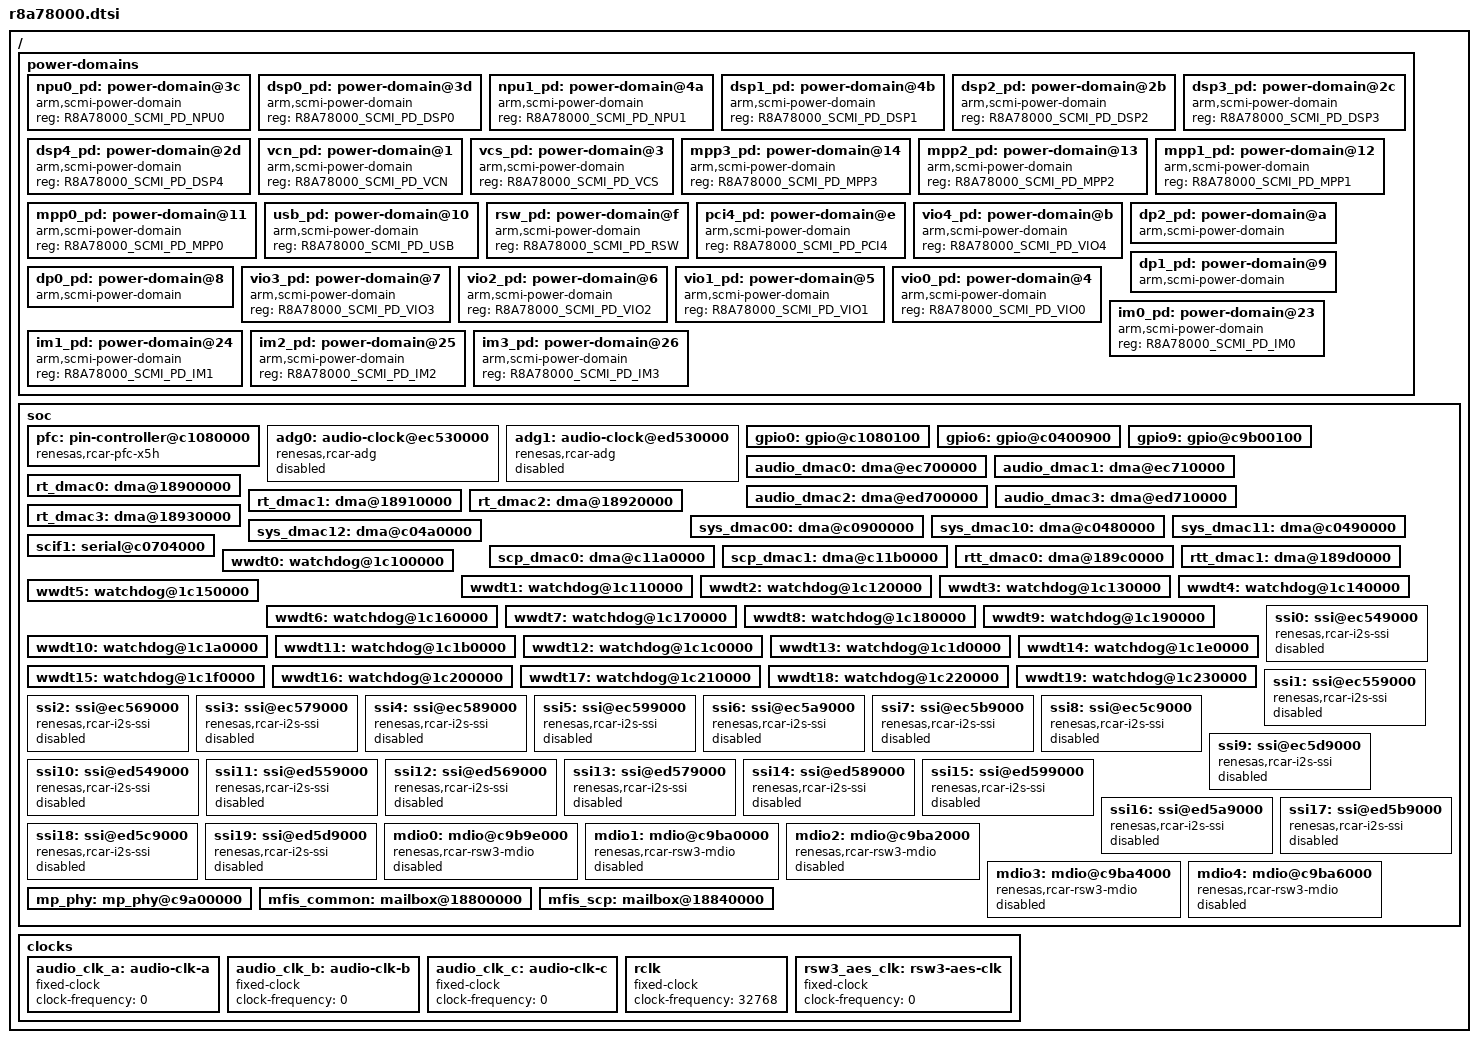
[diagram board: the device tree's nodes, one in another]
/*
 * Copyright (c) 2026 Renesas Electronics Corporation
 *
 * SPDX-License-Identifier: Apache-2.0
 */

#include <renesas/rcar/gen5/rcar_gen5_cr52.dtsi>
#include <zephyr/dt-bindings/clock/r8a78000_scmi_clock.h>
#include <zephyr/dt-bindings/clock/renesas_rcar_adg.h>
#include <zephyr/dt-bindings/power/r8a78000_scmi_power_domain.h>
#include <zephyr/dt-bindings/reset/r8a78000_scmi_reset_domain.h>

/ {
	power-domains {
		#address-cells = <1>;
		#size-cells = <0>;

		/*
		 * SCMI power domain IDs exported by the R-Car X5H V1 SCP firmware.
		 * These IDs index g_scmi_pd_config_table[] and are unrelated to the
		 * MDLC-local PDID values described by the hardware manual.
		 */
		npu0_pd: power-domain@3c {
			compatible = "arm,scmi-power-domain";
			reg = <R8A78000_SCMI_PD_NPU0>;
			#power-domain-cells = <0>;
		};

		dsp0_pd: power-domain@3d {
			compatible = "arm,scmi-power-domain";
			reg = <R8A78000_SCMI_PD_DSP0>;
			#power-domain-cells = <0>;
		};

		npu1_pd: power-domain@4a {
			compatible = "arm,scmi-power-domain";
			reg = <R8A78000_SCMI_PD_NPU1>;
			#power-domain-cells = <0>;
		};

		dsp1_pd: power-domain@4b {
			compatible = "arm,scmi-power-domain";
			reg = <R8A78000_SCMI_PD_DSP1>;
			#power-domain-cells = <0>;
		};

		dsp2_pd: power-domain@2b {
			compatible = "arm,scmi-power-domain";
			reg = <R8A78000_SCMI_PD_DSP2>;
			#power-domain-cells = <0>;
		};

		dsp3_pd: power-domain@2c {
			compatible = "arm,scmi-power-domain";
			reg = <R8A78000_SCMI_PD_DSP3>;
			#power-domain-cells = <0>;
		};

		dsp4_pd: power-domain@2d {
			compatible = "arm,scmi-power-domain";
			reg = <R8A78000_SCMI_PD_DSP4>;
			#power-domain-cells = <0>;
		};

		vcn_pd: power-domain@1 {
			compatible = "arm,scmi-power-domain";
			reg = <R8A78000_SCMI_PD_VCN>;
			#power-domain-cells = <0>;
		};

		vcs_pd: power-domain@3 {
			compatible = "arm,scmi-power-domain";
			reg = <R8A78000_SCMI_PD_VCS>;
			#power-domain-cells = <0>;
		};

		mpp3_pd: power-domain@14 {
			compatible = "arm,scmi-power-domain";
			reg = <R8A78000_SCMI_PD_MPP3>;
			#power-domain-cells = <0>;
		};

		mpp2_pd: power-domain@13 {
			compatible = "arm,scmi-power-domain";
			reg = <R8A78000_SCMI_PD_MPP2>;
			#power-domain-cells = <0>;
		};

		mpp1_pd: power-domain@12 {
			compatible = "arm,scmi-power-domain";
			reg = <R8A78000_SCMI_PD_MPP1>;
			#power-domain-cells = <0>;
		};

		mpp0_pd: power-domain@11 {
			compatible = "arm,scmi-power-domain";
			reg = <R8A78000_SCMI_PD_MPP0>;
			#power-domain-cells = <0>;
		};

		usb_pd: power-domain@10 {
			compatible = "arm,scmi-power-domain";
			reg = <R8A78000_SCMI_PD_USB>;
			#power-domain-cells = <0>;
		};

		rsw_pd: power-domain@f {
			compatible = "arm,scmi-power-domain";
			reg = <R8A78000_SCMI_PD_RSW>;
			#power-domain-cells = <0>;
		};

		pci4_pd: power-domain@e {
			compatible = "arm,scmi-power-domain";
			reg = <R8A78000_SCMI_PD_PCI4>;
			#power-domain-cells = <0>;
		};

		vio4_pd: power-domain@b {
			compatible = "arm,scmi-power-domain";
			reg = <R8A78000_SCMI_PD_VIO4>;
			#power-domain-cells = <0>;
		};

		dp2_pd: power-domain@a {
			compatible = "arm,scmi-power-domain";
			reg = <R8A78000_SCMI_PD_DP2>;
			#power-domain-cells = <0>;
			power-domains = <&vio4_pd>;
		};

		dp1_pd: power-domain@9 {
			compatible = "arm,scmi-power-domain";
			reg = <R8A78000_SCMI_PD_DP1>;
			#power-domain-cells = <0>;
			power-domains = <&vio4_pd>;
		};

		dp0_pd: power-domain@8 {
			compatible = "arm,scmi-power-domain";
			reg = <R8A78000_SCMI_PD_DP0>;
			#power-domain-cells = <0>;
			power-domains = <&vio4_pd>;
		};

		vio3_pd: power-domain@7 {
			compatible = "arm,scmi-power-domain";
			reg = <R8A78000_SCMI_PD_VIO3>;
			#power-domain-cells = <0>;
		};

		vio2_pd: power-domain@6 {
			compatible = "arm,scmi-power-domain";
			reg = <R8A78000_SCMI_PD_VIO2>;
			#power-domain-cells = <0>;
		};

		vio1_pd: power-domain@5 {
			compatible = "arm,scmi-power-domain";
			reg = <R8A78000_SCMI_PD_VIO1>;
			#power-domain-cells = <0>;
		};

		vio0_pd: power-domain@4 {
			compatible = "arm,scmi-power-domain";
			reg = <R8A78000_SCMI_PD_VIO0>;
			#power-domain-cells = <0>;
		};

		im0_pd: power-domain@23 {
			compatible = "arm,scmi-power-domain";
			reg = <R8A78000_SCMI_PD_IM0>;
			#power-domain-cells = <0>;
		};

		im1_pd: power-domain@24 {
			compatible = "arm,scmi-power-domain";
			reg = <R8A78000_SCMI_PD_IM1>;
			#power-domain-cells = <0>;
		};

		im2_pd: power-domain@25 {
			compatible = "arm,scmi-power-domain";
			reg = <R8A78000_SCMI_PD_IM2>;
			#power-domain-cells = <0>;
		};

		im3_pd: power-domain@26 {
			compatible = "arm,scmi-power-domain";
			reg = <R8A78000_SCMI_PD_IM3>;
			#power-domain-cells = <0>;
		};
	};

	soc {
		pfc: pin-controller@c1080000 {
			compatible = "renesas,rcar-pfc-x5h";
			reg = <0xc1080000 0x16c>, <0xc1080800 0x16c>,
			      <0xc1081000 0x16c>, <0xc0800000 0x16c>,
			      <0xc0800800 0x16c>, <0xc0400000 0x16c>,
			      <0xc0400800 0x16c>, <0xc0401000 0x16c>,
			      <0xc0401800 0x16c>, <0xc9b00000 0x16c>,
			      <0xc9b00800 0x16c>;
		};

		adg0: audio-clock@ec530000 {
			compatible = "renesas,rcar-adg";
			reg = <0xec530000 0x140>;
			clocks = <&scmi_clk R8A78000_SCMI_CLK_ADG0>,
				 <&scmi_clk R8A78000_SCMI_CLK_ADGHD1CK_MP_BUS>,
				 <&scmi_clk R8A78000_SCMI_CLK_ADGHD4CK_MP_BUS>,
				 <&audio_clk_a>, <&audio_clk_b>, <&audio_clk_c>;
			clock-names = "pclk", "s0d1", "s0d4",
				      "clk_a", "clk_b", "clk_c";
			#clock-cells = <1>;
			audio-clkout-sel = <ADG_CLKSRC(NONE) ADG_CLKSRC(NONE)
					    ADG_CLKSRC(NONE) ADG_CLKSRC(NONE)>;
			brga-clk-sel = <ADG_BRGSRC(S0D4)>;
			brgb-clk-sel = <ADG_BRGSRC(S0D4)>;
			status = "disabled";
		};

		adg1: audio-clock@ed530000 {
			compatible = "renesas,rcar-adg";
			reg = <0xed530000 0x140>;
			clocks = <&scmi_clk R8A78000_SCMI_CLK_ADG1>,
				 <&scmi_clk R8A78000_SCMI_CLK_ADGHD1CK_MP_BUS>,
				 <&scmi_clk R8A78000_SCMI_CLK_ADGHD4CK_MP_BUS>,
				 <&audio_clk_a>, <&audio_clk_b>, <&audio_clk_c>;
			clock-names = "pclk", "s0d1", "s0d4",
				      "clk_a", "clk_b", "clk_c";
			#clock-cells = <1>;
			audio-clkout-sel = <ADG_CLKSRC(NONE) ADG_CLKSRC(NONE)
					    ADG_CLKSRC(NONE) ADG_CLKSRC(NONE)>;
			brga-clk-sel = <ADG_BRGSRC(S0D4)>;
			brgb-clk-sel = <ADG_BRGSRC(S0D4)>;
			status = "disabled";
		};

		gpio0: gpio@c1080100 {
			interrupts = <GIC_SPI 0 IRQ_TYPE_LEVEL IRQ_DEFAULT_PRIORITY>;
			clocks = <&scmi_clk R8A78000_SCMI_CLK_PERE_GPIODM0>;
		};

		gpio6: gpio@c0400900 {
			interrupts = <GIC_SPI 24 IRQ_TYPE_LEVEL IRQ_DEFAULT_PRIORITY>;
			clocks = <&scmi_clk R8A78000_SCMI_CLK_PERE_GPIODM0>;
		};

		gpio9: gpio@c9b00100 {
			interrupts = <GIC_SPI 36 IRQ_TYPE_LEVEL IRQ_DEFAULT_PRIORITY>;
			clocks = <&scmi_clk R8A78000_SCMI_CLK_PERE_GPIODM0>;
		};

		audio_dmac0: dma@ec700000 {
			interrupts = <GIC_SPI 202 IRQ_TYPE_LEVEL IRQ_DEFAULT_PRIORITY>,
				     <GIC_SPI 203 IRQ_TYPE_LEVEL IRQ_DEFAULT_PRIORITY>,
				     <GIC_SPI 204 IRQ_TYPE_LEVEL IRQ_DEFAULT_PRIORITY>,
				     <GIC_SPI 205 IRQ_TYPE_LEVEL IRQ_DEFAULT_PRIORITY>,
				     <GIC_SPI 206 IRQ_TYPE_LEVEL IRQ_DEFAULT_PRIORITY>,
				     <GIC_SPI 207 IRQ_TYPE_LEVEL IRQ_DEFAULT_PRIORITY>,
				     <GIC_SPI 208 IRQ_TYPE_LEVEL IRQ_DEFAULT_PRIORITY>,
				     <GIC_SPI 209 IRQ_TYPE_LEVEL IRQ_DEFAULT_PRIORITY>;
			interrupt-names = "ch0", "ch2", "ch4", "ch6",
					  "ch8", "ch10", "ch12", "ch14";
		};

		audio_dmac1: dma@ec710000 {
			interrupts = <GIC_SPI 210 IRQ_TYPE_LEVEL IRQ_DEFAULT_PRIORITY>,
				     <GIC_SPI 211 IRQ_TYPE_LEVEL IRQ_DEFAULT_PRIORITY>,
				     <GIC_SPI 212 IRQ_TYPE_LEVEL IRQ_DEFAULT_PRIORITY>,
				     <GIC_SPI 213 IRQ_TYPE_LEVEL IRQ_DEFAULT_PRIORITY>,
				     <GIC_SPI 214 IRQ_TYPE_LEVEL IRQ_DEFAULT_PRIORITY>,
				     <GIC_SPI 215 IRQ_TYPE_LEVEL IRQ_DEFAULT_PRIORITY>,
				     <GIC_SPI 216 IRQ_TYPE_LEVEL IRQ_DEFAULT_PRIORITY>,
				     <GIC_SPI 217 IRQ_TYPE_LEVEL IRQ_DEFAULT_PRIORITY>;
			interrupt-names = "ch0", "ch2", "ch4", "ch6",
					  "ch8", "ch10", "ch12", "ch14";
		};

		audio_dmac2: dma@ed700000 {
			interrupts = <GIC_SPI 218 IRQ_TYPE_LEVEL IRQ_DEFAULT_PRIORITY>,
				     <GIC_SPI 219 IRQ_TYPE_LEVEL IRQ_DEFAULT_PRIORITY>,
				     <GIC_SPI 220 IRQ_TYPE_LEVEL IRQ_DEFAULT_PRIORITY>,
				     <GIC_SPI 221 IRQ_TYPE_LEVEL IRQ_DEFAULT_PRIORITY>,
				     <GIC_SPI 222 IRQ_TYPE_LEVEL IRQ_DEFAULT_PRIORITY>,
				     <GIC_SPI 223 IRQ_TYPE_LEVEL IRQ_DEFAULT_PRIORITY>,
				     <GIC_SPI 224 IRQ_TYPE_LEVEL IRQ_DEFAULT_PRIORITY>,
				     <GIC_SPI 225 IRQ_TYPE_LEVEL IRQ_DEFAULT_PRIORITY>;
			interrupt-names = "ch0", "ch2", "ch4", "ch6",
					  "ch8", "ch10", "ch12", "ch14";
		};

		audio_dmac3: dma@ed710000 {
			interrupts = <GIC_SPI 226 IRQ_TYPE_LEVEL IRQ_DEFAULT_PRIORITY>,
				     <GIC_SPI 227 IRQ_TYPE_LEVEL IRQ_DEFAULT_PRIORITY>,
				     <GIC_SPI 228 IRQ_TYPE_LEVEL IRQ_DEFAULT_PRIORITY>,
				     <GIC_SPI 229 IRQ_TYPE_LEVEL IRQ_DEFAULT_PRIORITY>,
				     <GIC_SPI 230 IRQ_TYPE_LEVEL IRQ_DEFAULT_PRIORITY>,
				     <GIC_SPI 231 IRQ_TYPE_LEVEL IRQ_DEFAULT_PRIORITY>,
				     <GIC_SPI 232 IRQ_TYPE_LEVEL IRQ_DEFAULT_PRIORITY>,
				     <GIC_SPI 233 IRQ_TYPE_LEVEL IRQ_DEFAULT_PRIORITY>;
			interrupt-names = "ch0", "ch2", "ch4", "ch6",
					  "ch8", "ch10", "ch12", "ch14";
		};

		rt_dmac0: dma@18900000 {
			interrupts = <GIC_SPI 242 IRQ_TYPE_LEVEL IRQ_DEFAULT_PRIORITY>,
				     <GIC_SPI 243 IRQ_TYPE_LEVEL IRQ_DEFAULT_PRIORITY>,
				     <GIC_SPI 244 IRQ_TYPE_LEVEL IRQ_DEFAULT_PRIORITY>,
				     <GIC_SPI 245 IRQ_TYPE_LEVEL IRQ_DEFAULT_PRIORITY>,
				     <GIC_SPI 246 IRQ_TYPE_LEVEL IRQ_DEFAULT_PRIORITY>,
				     <GIC_SPI 247 IRQ_TYPE_LEVEL IRQ_DEFAULT_PRIORITY>,
				     <GIC_SPI 248 IRQ_TYPE_LEVEL IRQ_DEFAULT_PRIORITY>,
				     <GIC_SPI 249 IRQ_TYPE_LEVEL IRQ_DEFAULT_PRIORITY>;
			interrupt-names = "ch0", "ch2", "ch4", "ch6",
					  "ch8", "ch10", "ch12", "ch14";
		};

		rt_dmac1: dma@18910000 {
			interrupts = <GIC_SPI 250 IRQ_TYPE_LEVEL IRQ_DEFAULT_PRIORITY>,
				     <GIC_SPI 251 IRQ_TYPE_LEVEL IRQ_DEFAULT_PRIORITY>,
				     <GIC_SPI 252 IRQ_TYPE_LEVEL IRQ_DEFAULT_PRIORITY>,
				     <GIC_SPI 253 IRQ_TYPE_LEVEL IRQ_DEFAULT_PRIORITY>,
				     <GIC_SPI 254 IRQ_TYPE_LEVEL IRQ_DEFAULT_PRIORITY>,
				     <GIC_SPI 255 IRQ_TYPE_LEVEL IRQ_DEFAULT_PRIORITY>,
				     <GIC_SPI 256 IRQ_TYPE_LEVEL IRQ_DEFAULT_PRIORITY>,
				     <GIC_SPI 257 IRQ_TYPE_LEVEL IRQ_DEFAULT_PRIORITY>;
			interrupt-names = "ch0", "ch2", "ch4", "ch6",
					  "ch8", "ch10", "ch12", "ch14";
		};

		rt_dmac2: dma@18920000 {
			interrupts = <GIC_SPI 258 IRQ_TYPE_LEVEL IRQ_DEFAULT_PRIORITY>,
				     <GIC_SPI 259 IRQ_TYPE_LEVEL IRQ_DEFAULT_PRIORITY>,
				     <GIC_SPI 260 IRQ_TYPE_LEVEL IRQ_DEFAULT_PRIORITY>,
				     <GIC_SPI 261 IRQ_TYPE_LEVEL IRQ_DEFAULT_PRIORITY>,
				     <GIC_SPI 262 IRQ_TYPE_LEVEL IRQ_DEFAULT_PRIORITY>,
				     <GIC_SPI 263 IRQ_TYPE_LEVEL IRQ_DEFAULT_PRIORITY>,
				     <GIC_SPI 264 IRQ_TYPE_LEVEL IRQ_DEFAULT_PRIORITY>,
				     <GIC_SPI 265 IRQ_TYPE_LEVEL IRQ_DEFAULT_PRIORITY>;
			interrupt-names = "ch0", "ch2", "ch4", "ch6",
					  "ch8", "ch10", "ch12", "ch14";
		};

		rt_dmac3: dma@18930000 {
			interrupts = <GIC_SPI 266 IRQ_TYPE_LEVEL IRQ_DEFAULT_PRIORITY>,
				     <GIC_SPI 267 IRQ_TYPE_LEVEL IRQ_DEFAULT_PRIORITY>,
				     <GIC_SPI 268 IRQ_TYPE_LEVEL IRQ_DEFAULT_PRIORITY>,
				     <GIC_SPI 269 IRQ_TYPE_LEVEL IRQ_DEFAULT_PRIORITY>,
				     <GIC_SPI 270 IRQ_TYPE_LEVEL IRQ_DEFAULT_PRIORITY>,
				     <GIC_SPI 271 IRQ_TYPE_LEVEL IRQ_DEFAULT_PRIORITY>,
				     <GIC_SPI 272 IRQ_TYPE_LEVEL IRQ_DEFAULT_PRIORITY>,
				     <GIC_SPI 273 IRQ_TYPE_LEVEL IRQ_DEFAULT_PRIORITY>;
			interrupt-names = "ch0", "ch2", "ch4", "ch6",
					  "ch8", "ch10", "ch12", "ch14";
		};

		sys_dmac00: dma@c0900000 {
			interrupts = <GIC_SPI 282 IRQ_TYPE_LEVEL IRQ_DEFAULT_PRIORITY>,
				     <GIC_SPI 283 IRQ_TYPE_LEVEL IRQ_DEFAULT_PRIORITY>,
				     <GIC_SPI 284 IRQ_TYPE_LEVEL IRQ_DEFAULT_PRIORITY>,
				     <GIC_SPI 285 IRQ_TYPE_LEVEL IRQ_DEFAULT_PRIORITY>,
				     <GIC_SPI 286 IRQ_TYPE_LEVEL IRQ_DEFAULT_PRIORITY>,
				     <GIC_SPI 287 IRQ_TYPE_LEVEL IRQ_DEFAULT_PRIORITY>,
				     <GIC_SPI 288 IRQ_TYPE_LEVEL IRQ_DEFAULT_PRIORITY>,
				     <GIC_SPI 289 IRQ_TYPE_LEVEL IRQ_DEFAULT_PRIORITY>;
			interrupt-names = "ch0", "ch2", "ch4", "ch6",
					  "ch8", "ch10", "ch12", "ch14";
		};

		sys_dmac10: dma@c0480000 {
			interrupts = <GIC_SPI 290 IRQ_TYPE_LEVEL IRQ_DEFAULT_PRIORITY>,
				     <GIC_SPI 291 IRQ_TYPE_LEVEL IRQ_DEFAULT_PRIORITY>,
				     <GIC_SPI 292 IRQ_TYPE_LEVEL IRQ_DEFAULT_PRIORITY>,
				     <GIC_SPI 293 IRQ_TYPE_LEVEL IRQ_DEFAULT_PRIORITY>,
				     <GIC_SPI 294 IRQ_TYPE_LEVEL IRQ_DEFAULT_PRIORITY>,
				     <GIC_SPI 295 IRQ_TYPE_LEVEL IRQ_DEFAULT_PRIORITY>,
				     <GIC_SPI 296 IRQ_TYPE_LEVEL IRQ_DEFAULT_PRIORITY>,
				     <GIC_SPI 297 IRQ_TYPE_LEVEL IRQ_DEFAULT_PRIORITY>;
			interrupt-names = "ch0", "ch2", "ch4", "ch6",
					  "ch8", "ch10", "ch12", "ch14";
		};

		sys_dmac11: dma@c0490000 {
			interrupts = <GIC_SPI 298 IRQ_TYPE_LEVEL IRQ_DEFAULT_PRIORITY>,
				     <GIC_SPI 299 IRQ_TYPE_LEVEL IRQ_DEFAULT_PRIORITY>,
				     <GIC_SPI 300 IRQ_TYPE_LEVEL IRQ_DEFAULT_PRIORITY>,
				     <GIC_SPI 301 IRQ_TYPE_LEVEL IRQ_DEFAULT_PRIORITY>,
				     <GIC_SPI 302 IRQ_TYPE_LEVEL IRQ_DEFAULT_PRIORITY>,
				     <GIC_SPI 303 IRQ_TYPE_LEVEL IRQ_DEFAULT_PRIORITY>,
				     <GIC_SPI 304 IRQ_TYPE_LEVEL IRQ_DEFAULT_PRIORITY>,
				     <GIC_SPI 305 IRQ_TYPE_LEVEL IRQ_DEFAULT_PRIORITY>;
			interrupt-names = "ch0", "ch2", "ch4", "ch6",
					  "ch8", "ch10", "ch12", "ch14";
		};

		sys_dmac12: dma@c04a0000 {
			interrupts = <GIC_SPI 306 IRQ_TYPE_LEVEL IRQ_DEFAULT_PRIORITY>,
				     <GIC_SPI 307 IRQ_TYPE_LEVEL IRQ_DEFAULT_PRIORITY>,
				     <GIC_SPI 308 IRQ_TYPE_LEVEL IRQ_DEFAULT_PRIORITY>,
				     <GIC_SPI 309 IRQ_TYPE_LEVEL IRQ_DEFAULT_PRIORITY>,
				     <GIC_SPI 310 IRQ_TYPE_LEVEL IRQ_DEFAULT_PRIORITY>,
				     <GIC_SPI 311 IRQ_TYPE_LEVEL IRQ_DEFAULT_PRIORITY>,
				     <GIC_SPI 312 IRQ_TYPE_LEVEL IRQ_DEFAULT_PRIORITY>,
				     <GIC_SPI 313 IRQ_TYPE_LEVEL IRQ_DEFAULT_PRIORITY>;
			interrupt-names = "ch0", "ch2", "ch4", "ch6",
					  "ch8", "ch10", "ch12", "ch14";
		};

		scp_dmac0: dma@c11a0000 {
			interrupts = <GIC_SPI 793 IRQ_TYPE_LEVEL IRQ_DEFAULT_PRIORITY>,
				     <GIC_SPI 794 IRQ_TYPE_LEVEL IRQ_DEFAULT_PRIORITY>,
				     <GIC_SPI 795 IRQ_TYPE_LEVEL IRQ_DEFAULT_PRIORITY>,
				     <GIC_SPI 796 IRQ_TYPE_LEVEL IRQ_DEFAULT_PRIORITY>,
				     <GIC_SPI 797 IRQ_TYPE_LEVEL IRQ_DEFAULT_PRIORITY>,
				     <GIC_SPI 798 IRQ_TYPE_LEVEL IRQ_DEFAULT_PRIORITY>,
				     <GIC_SPI 799 IRQ_TYPE_LEVEL IRQ_DEFAULT_PRIORITY>,
				     <GIC_SPI 800 IRQ_TYPE_LEVEL IRQ_DEFAULT_PRIORITY>;
			interrupt-names = "ch0", "ch2", "ch4", "ch6",
					  "ch8", "ch10", "ch12", "ch14";
		};

		scp_dmac1: dma@c11b0000 {
			interrupts = <GIC_SPI 803 IRQ_TYPE_LEVEL IRQ_DEFAULT_PRIORITY>,
				     <GIC_SPI 804 IRQ_TYPE_LEVEL IRQ_DEFAULT_PRIORITY>,
				     <GIC_SPI 805 IRQ_TYPE_LEVEL IRQ_DEFAULT_PRIORITY>,
				     <GIC_SPI 806 IRQ_TYPE_LEVEL IRQ_DEFAULT_PRIORITY>,
				     <GIC_SPI 807 IRQ_TYPE_LEVEL IRQ_DEFAULT_PRIORITY>,
				     <GIC_SPI 808 IRQ_TYPE_LEVEL IRQ_DEFAULT_PRIORITY>,
				     <GIC_SPI 809 IRQ_TYPE_LEVEL IRQ_DEFAULT_PRIORITY>,
				     <GIC_SPI 810 IRQ_TYPE_LEVEL IRQ_DEFAULT_PRIORITY>;
			interrupt-names = "ch0", "ch2", "ch4", "ch6",
					  "ch8", "ch10", "ch12", "ch14";
		};

		rtt_dmac0: dma@189c0000 {
			interrupts = <GIC_SPI 732 IRQ_TYPE_LEVEL IRQ_DEFAULT_PRIORITY>,
				     <GIC_SPI 733 IRQ_TYPE_LEVEL IRQ_DEFAULT_PRIORITY>,
				     <GIC_SPI 734 IRQ_TYPE_LEVEL IRQ_DEFAULT_PRIORITY>,
				     <GIC_SPI 735 IRQ_TYPE_LEVEL IRQ_DEFAULT_PRIORITY>,
				     <GIC_SPI 736 IRQ_TYPE_LEVEL IRQ_DEFAULT_PRIORITY>,
				     <GIC_SPI 737 IRQ_TYPE_LEVEL IRQ_DEFAULT_PRIORITY>,
				     <GIC_SPI 738 IRQ_TYPE_LEVEL IRQ_DEFAULT_PRIORITY>,
				     <GIC_SPI 739 IRQ_TYPE_LEVEL IRQ_DEFAULT_PRIORITY>,
				     <GIC_SPI 740 IRQ_TYPE_LEVEL IRQ_DEFAULT_PRIORITY>,
				     <GIC_SPI 741 IRQ_TYPE_LEVEL IRQ_DEFAULT_PRIORITY>,
				     <GIC_SPI 742 IRQ_TYPE_LEVEL IRQ_DEFAULT_PRIORITY>,
				     <GIC_SPI 743 IRQ_TYPE_LEVEL IRQ_DEFAULT_PRIORITY>,
				     <GIC_SPI 744 IRQ_TYPE_LEVEL IRQ_DEFAULT_PRIORITY>,
				     <GIC_SPI 745 IRQ_TYPE_LEVEL IRQ_DEFAULT_PRIORITY>,
				     <GIC_SPI 746 IRQ_TYPE_LEVEL IRQ_DEFAULT_PRIORITY>,
				     <GIC_SPI 747 IRQ_TYPE_LEVEL IRQ_DEFAULT_PRIORITY>;
			interrupt-names = "ch0", "ch1", "ch2", "ch3",
					  "ch4", "ch5", "ch6", "ch7",
					  "ch8", "ch9", "ch10", "ch11",
					  "ch12", "ch13", "ch14", "ch15";
		};

		rtt_dmac1: dma@189d0000 {
			interrupts = <GIC_SPI 748 IRQ_TYPE_LEVEL IRQ_DEFAULT_PRIORITY>,
				     <GIC_SPI 749 IRQ_TYPE_LEVEL IRQ_DEFAULT_PRIORITY>,
				     <GIC_SPI 750 IRQ_TYPE_LEVEL IRQ_DEFAULT_PRIORITY>,
				     <GIC_SPI 751 IRQ_TYPE_LEVEL IRQ_DEFAULT_PRIORITY>,
				     <GIC_SPI 752 IRQ_TYPE_LEVEL IRQ_DEFAULT_PRIORITY>,
				     <GIC_SPI 753 IRQ_TYPE_LEVEL IRQ_DEFAULT_PRIORITY>,
				     <GIC_SPI 754 IRQ_TYPE_LEVEL IRQ_DEFAULT_PRIORITY>,
				     <GIC_SPI 755 IRQ_TYPE_LEVEL IRQ_DEFAULT_PRIORITY>,
				     <GIC_SPI 756 IRQ_TYPE_LEVEL IRQ_DEFAULT_PRIORITY>,
				     <GIC_SPI 757 IRQ_TYPE_LEVEL IRQ_DEFAULT_PRIORITY>,
				     <GIC_SPI 758 IRQ_TYPE_LEVEL IRQ_DEFAULT_PRIORITY>,
				     <GIC_SPI 759 IRQ_TYPE_LEVEL IRQ_DEFAULT_PRIORITY>,
				     <GIC_SPI 760 IRQ_TYPE_LEVEL IRQ_DEFAULT_PRIORITY>,
				     <GIC_SPI 761 IRQ_TYPE_LEVEL IRQ_DEFAULT_PRIORITY>,
				     <GIC_SPI 762 IRQ_TYPE_LEVEL IRQ_DEFAULT_PRIORITY>,
				     <GIC_SPI 763 IRQ_TYPE_LEVEL IRQ_DEFAULT_PRIORITY>;
			interrupt-names = "ch0", "ch1", "ch2", "ch3",
					  "ch4", "ch5", "ch6", "ch7",
					  "ch8", "ch9", "ch10", "ch11",
					  "ch12", "ch13", "ch14", "ch15";
		};

		scif1: serial@c0704000 {
			interrupts = <GIC_SPI 588 IRQ_TYPE_LEVEL IRQ_DEFAULT_PRIORITY>;
			clocks = <&scmi_clk R8A78000_SCMI_CLK_SCIF1>, /* Mod clk */
				 <&scmi_clk R8A78000_SCMI_CLK_SGAD16_PERW_BUS>; /* Bus clk */
		};

		wwdt0: watchdog@1c100000 {
			interrupts = <GIC_SPI 655 IRQ_TYPE_LEVEL IRQ_DEFAULT_PRIORITY>;
			clocks = <&rclk>;
			resets = <&scmi_reset R8A78000_SCMI_RESET_WWDT00>,
				 <&scmi_reset R8A78000_SCMI_RESET_WWDT01>;
			warning-irq-enabled;
		};

		wwdt1: watchdog@1c110000 {
			interrupts = <GIC_SPI 656 IRQ_TYPE_LEVEL IRQ_DEFAULT_PRIORITY>;
			clocks = <&rclk>;
			resets = <&scmi_reset R8A78000_SCMI_RESET_WWDT10>,
				 <&scmi_reset R8A78000_SCMI_RESET_WWDT11>;
			warning-irq-enabled;
		};

		wwdt2: watchdog@1c120000 {
			interrupts = <GIC_SPI 657 IRQ_TYPE_LEVEL IRQ_DEFAULT_PRIORITY>;
			clocks = <&rclk>;
			resets = <&scmi_reset R8A78000_SCMI_RESET_WWDT20>,
				 <&scmi_reset R8A78000_SCMI_RESET_WWDT21>;
			warning-irq-enabled;
		};

		wwdt3: watchdog@1c130000 {
			interrupts = <GIC_SPI 658 IRQ_TYPE_LEVEL IRQ_DEFAULT_PRIORITY>;
			clocks = <&rclk>;
			resets = <&scmi_reset R8A78000_SCMI_RESET_WWDT30>,
				 <&scmi_reset R8A78000_SCMI_RESET_WWDT31>;
			warning-irq-enabled;
		};

		wwdt4: watchdog@1c140000 {
			interrupts = <GIC_SPI 659 IRQ_TYPE_LEVEL IRQ_DEFAULT_PRIORITY>;
			clocks = <&rclk>;
			resets = <&scmi_reset R8A78000_SCMI_RESET_WWDT40>,
				 <&scmi_reset R8A78000_SCMI_RESET_WWDT41>;
			warning-irq-enabled;
		};

		wwdt5: watchdog@1c150000 {
			interrupts = <GIC_SPI 660 IRQ_TYPE_LEVEL IRQ_DEFAULT_PRIORITY>;
			clocks = <&rclk>;
			resets = <&scmi_reset R8A78000_SCMI_RESET_WWDT50>,
				 <&scmi_reset R8A78000_SCMI_RESET_WWDT51>;
			warning-irq-enabled;
		};

		wwdt6: watchdog@1c160000 {
			interrupts = <GIC_SPI 661 IRQ_TYPE_LEVEL IRQ_DEFAULT_PRIORITY>;
			clocks = <&rclk>;
			resets = <&scmi_reset R8A78000_SCMI_RESET_WWDT60>,
				 <&scmi_reset R8A78000_SCMI_RESET_WWDT61>;
			warning-irq-enabled;
		};

		wwdt7: watchdog@1c170000 {
			interrupts = <GIC_SPI 662 IRQ_TYPE_LEVEL IRQ_DEFAULT_PRIORITY>;
			clocks = <&rclk>;
			resets = <&scmi_reset R8A78000_SCMI_RESET_WWDT70>,
				 <&scmi_reset R8A78000_SCMI_RESET_WWDT71>;
			warning-irq-enabled;
		};

		wwdt8: watchdog@1c180000 {
			interrupts = <GIC_SPI 663 IRQ_TYPE_LEVEL IRQ_DEFAULT_PRIORITY>;
			clocks = <&rclk>;
			resets = <&scmi_reset R8A78000_SCMI_RESET_WWDT80>,
				 <&scmi_reset R8A78000_SCMI_RESET_WWDT81>;
			warning-irq-enabled;
		};

		wwdt9: watchdog@1c190000 {
			interrupts = <GIC_SPI 664 IRQ_TYPE_LEVEL IRQ_DEFAULT_PRIORITY>;
			clocks = <&rclk>;
			resets = <&scmi_reset R8A78000_SCMI_RESET_WWDT90>,
				 <&scmi_reset R8A78000_SCMI_RESET_WWDT91>;
			warning-irq-enabled;
		};

		wwdt10: watchdog@1c1a0000 {
			interrupts = <GIC_SPI 665 IRQ_TYPE_LEVEL IRQ_DEFAULT_PRIORITY>;
			clocks = <&rclk>;
			resets = <&scmi_reset R8A78000_SCMI_RESET_WWDT100>,
				 <&scmi_reset R8A78000_SCMI_RESET_WWDT101>;
			warning-irq-enabled;
		};

		wwdt11: watchdog@1c1b0000 {
			interrupts = <GIC_SPI 666 IRQ_TYPE_LEVEL IRQ_DEFAULT_PRIORITY>;
			clocks = <&rclk>;
			resets = <&scmi_reset R8A78000_SCMI_RESET_WWDT110>,
				 <&scmi_reset R8A78000_SCMI_RESET_WWDT111>;
			warning-irq-enabled;
		};

		wwdt12: watchdog@1c1c0000 {
			interrupts = <GIC_SPI 667 IRQ_TYPE_LEVEL IRQ_DEFAULT_PRIORITY>;
			clocks = <&rclk>;
			resets = <&scmi_reset R8A78000_SCMI_RESET_WWDT120>,
				 <&scmi_reset R8A78000_SCMI_RESET_WWDT121>;
			warning-irq-enabled;
		};

		wwdt13: watchdog@1c1d0000 {
			interrupts = <GIC_SPI 668 IRQ_TYPE_LEVEL IRQ_DEFAULT_PRIORITY>;
			clocks = <&rclk>;
			resets = <&scmi_reset R8A78000_SCMI_RESET_WWDT130>,
				 <&scmi_reset R8A78000_SCMI_RESET_WWDT131>;
			warning-irq-enabled;
		};

		wwdt14: watchdog@1c1e0000 {
			interrupts = <GIC_SPI 669 IRQ_TYPE_LEVEL IRQ_DEFAULT_PRIORITY>;
			clocks = <&rclk>;
			resets = <&scmi_reset R8A78000_SCMI_RESET_WWDT140>,
				 <&scmi_reset R8A78000_SCMI_RESET_WWDT141>;
			warning-irq-enabled;
		};

		wwdt15: watchdog@1c1f0000 {
			interrupts = <GIC_SPI 670 IRQ_TYPE_LEVEL IRQ_DEFAULT_PRIORITY>;
			clocks = <&rclk>;
			resets = <&scmi_reset R8A78000_SCMI_RESET_WWDT150>,
				 <&scmi_reset R8A78000_SCMI_RESET_WWDT151>;
			warning-irq-enabled;
		};

		wwdt16: watchdog@1c200000 {
			interrupts = <GIC_SPI 671 IRQ_TYPE_LEVEL IRQ_DEFAULT_PRIORITY>;
			clocks = <&rclk>;
			resets = <&scmi_reset R8A78000_SCMI_RESET_WWDT160>,
				 <&scmi_reset R8A78000_SCMI_RESET_WWDT161>;
			warning-irq-enabled;
		};

		wwdt17: watchdog@1c210000 {
			interrupts = <GIC_SPI 672 IRQ_TYPE_LEVEL IRQ_DEFAULT_PRIORITY>;
			clocks = <&rclk>;
			resets = <&scmi_reset R8A78000_SCMI_RESET_WWDT170>,
				 <&scmi_reset R8A78000_SCMI_RESET_WWDT171>;
			warning-irq-enabled;
		};

		wwdt18: watchdog@1c220000 {
			interrupts = <GIC_SPI 673 IRQ_TYPE_LEVEL IRQ_DEFAULT_PRIORITY>;
			clocks = <&rclk>;
			resets = <&scmi_reset R8A78000_SCMI_RESET_WWDT180>,
				 <&scmi_reset R8A78000_SCMI_RESET_WWDT181>;
			warning-irq-enabled;
		};

		wwdt19: watchdog@1c230000 {
			interrupts = <GIC_SPI 674 IRQ_TYPE_LEVEL IRQ_DEFAULT_PRIORITY>;
			clocks = <&rclk>;
			resets = <&scmi_reset R8A78000_SCMI_RESET_WWDT190>,
				 <&scmi_reset R8A78000_SCMI_RESET_WWDT191>;
			warning-irq-enabled;
		};

		ssi0: ssi@ec549000 {
			compatible = "renesas,rcar-i2s-ssi";
			reg = <0xec549000 0x34>,
			      <0xec540000 0xa004>,
			      <0xec100000 0x7004>;
			reg-names = "ssi", "ssiu", "ssip";
			dmas = <&audio_dmac0 0 0x7c>,
			       <&audio_dmac0 1 0x7d>;
			dma-names = "rx", "tx";
			interrupts = <GIC_SPI 513 IRQ_TYPE_LEVEL IRQ_DEFAULT_PRIORITY>;
			clocks = <&scmi_clk R8A78000_SCMI_CLK_SSI00>,
				 <&scmi_clk R8A78000_SCMI_CLK_SSI0>,
				 <&adg0 ADG_CLKSRC(BRGA)>;
			clock-names = "ssi", "ssi-domain", "audio-clk";
			#address-cells = <1>;
			#size-cells = <0>;
			status = "disabled";
		};

		ssi1: ssi@ec559000 {
			compatible = "renesas,rcar-i2s-ssi";
			reg = <0xec559000 0x34>,
			      <0xec550000 0xa004>,
			      <0xec108000 0x7004>;
			reg-names = "ssi", "ssiu", "ssip";
			dmas = <&audio_dmac0 0 0x6c>,
			       <&audio_dmac0 1 0x6d>;
			dma-names = "rx", "tx";
			interrupts = <GIC_SPI 514 IRQ_TYPE_LEVEL IRQ_DEFAULT_PRIORITY>;
			clocks = <&scmi_clk R8A78000_SCMI_CLK_SSI01>,
				 <&scmi_clk R8A78000_SCMI_CLK_SSI0>,
				 <&adg0 ADG_CLKSRC(BRGA)>;
			clock-names = "ssi", "ssi-domain", "audio-clk";
			#address-cells = <1>;
			#size-cells = <0>;
			status = "disabled";
		};

		ssi2: ssi@ec569000 {
			compatible = "renesas,rcar-i2s-ssi";
			reg = <0xec569000 0x34>,
			      <0xec560000 0xa004>,
			      <0xec110000 0x7004>;
			reg-names = "ssi", "ssiu", "ssip";
			dmas = <&audio_dmac0 0 0x5c>,
			       <&audio_dmac0 1 0x5d>;
			dma-names = "rx", "tx";
			interrupts = <GIC_SPI 515 IRQ_TYPE_LEVEL IRQ_DEFAULT_PRIORITY>;
			clocks = <&scmi_clk R8A78000_SCMI_CLK_SSI02>,
				 <&scmi_clk R8A78000_SCMI_CLK_SSI0>,
				 <&adg0 ADG_CLKSRC(BRGA)>;
			clock-names = "ssi", "ssi-domain", "audio-clk";
			#address-cells = <1>;
			#size-cells = <0>;
			status = "disabled";
		};

		ssi3: ssi@ec579000 {
			compatible = "renesas,rcar-i2s-ssi";
			reg = <0xec579000 0x34>,
			      <0xec570000 0xa004>,
			      <0xec118000 0x7004>;
			reg-names = "ssi", "ssiu", "ssip";
			dmas = <&audio_dmac0 0 0x4c>,
			       <&audio_dmac0 1 0x4d>;
			dma-names = "rx", "tx";
			interrupts = <GIC_SPI 516 IRQ_TYPE_LEVEL IRQ_DEFAULT_PRIORITY>;
			clocks = <&scmi_clk R8A78000_SCMI_CLK_SSI03>,
				 <&scmi_clk R8A78000_SCMI_CLK_SSI0>,
				 <&adg0 ADG_CLKSRC(BRGA)>;
			clock-names = "ssi", "ssi-domain", "audio-clk";
			#address-cells = <1>;
			#size-cells = <0>;
			status = "disabled";
		};

		ssi4: ssi@ec589000 {
			compatible = "renesas,rcar-i2s-ssi";
			reg = <0xec589000 0x34>,
			      <0xec580000 0xa004>,
			      <0xec120000 0x7004>;
			reg-names = "ssi", "ssiu", "ssip";
			dmas = <&audio_dmac0 0 0x3c>,
			       <&audio_dmac0 1 0x3d>;
			dma-names = "rx", "tx";
			interrupts = <GIC_SPI 517 IRQ_TYPE_LEVEL IRQ_DEFAULT_PRIORITY>;
			clocks = <&scmi_clk R8A78000_SCMI_CLK_SSI04>,
				 <&scmi_clk R8A78000_SCMI_CLK_SSI0>,
				 <&adg0 ADG_CLKSRC(BRGA)>;
			clock-names = "ssi", "ssi-domain", "audio-clk";
			#address-cells = <1>;
			#size-cells = <0>;
			status = "disabled";
		};

		ssi5: ssi@ec599000 {
			compatible = "renesas,rcar-i2s-ssi";
			reg = <0xec599000 0x34>,
			      <0xec590000 0xa004>,
			      <0xec128000 0x7004>;
			reg-names = "ssi", "ssiu", "ssip";
			dmas = <&audio_dmac0 0 0x2c>,
			       <&audio_dmac0 1 0x2d>;
			dma-names = "rx", "tx";
			interrupts = <GIC_SPI 518 IRQ_TYPE_LEVEL IRQ_DEFAULT_PRIORITY>;
			clocks = <&scmi_clk R8A78000_SCMI_CLK_SSI05>,
				 <&scmi_clk R8A78000_SCMI_CLK_SSI0>,
				 <&adg0 ADG_CLKSRC(BRGA)>;
			clock-names = "ssi", "ssi-domain", "audio-clk";
			#address-cells = <1>;
			#size-cells = <0>;
			status = "disabled";
		};

		ssi6: ssi@ec5a9000 {
			compatible = "renesas,rcar-i2s-ssi";
			reg = <0xec5a9000 0x34>,
			      <0xec5a0000 0xa004>,
			      <0xec130000 0x7004>;
			reg-names = "ssi", "ssiu", "ssip";
			dmas = <&audio_dmac0 0 0x2a>,
			       <&audio_dmac0 1 0x2b>;
			dma-names = "rx", "tx";
			interrupts = <GIC_SPI 519 IRQ_TYPE_LEVEL IRQ_DEFAULT_PRIORITY>;
			clocks = <&scmi_clk R8A78000_SCMI_CLK_SSI06>,
				 <&scmi_clk R8A78000_SCMI_CLK_SSI0>,
				 <&adg0 ADG_CLKSRC(BRGA)>;
			clock-names = "ssi", "ssi-domain", "audio-clk";
			#address-cells = <1>;
			#size-cells = <0>;
			status = "disabled";
		};

		ssi7: ssi@ec5b9000 {
			compatible = "renesas,rcar-i2s-ssi";
			reg = <0xec5b9000 0x34>,
			      <0xec5b0000 0xa004>,
			      <0xec138000 0x7004>;
			reg-names = "ssi", "ssiu", "ssip";
			dmas = <&audio_dmac0 0 0x28>,
			       <&audio_dmac0 1 0x29>;
			dma-names = "rx", "tx";
			interrupts = <GIC_SPI 520 IRQ_TYPE_LEVEL IRQ_DEFAULT_PRIORITY>;
			clocks = <&scmi_clk R8A78000_SCMI_CLK_SSI07>,
				 <&scmi_clk R8A78000_SCMI_CLK_SSI0>,
				 <&adg0 ADG_CLKSRC(BRGA)>;
			clock-names = "ssi", "ssi-domain", "audio-clk";
			#address-cells = <1>;
			#size-cells = <0>;
			status = "disabled";
		};

		ssi8: ssi@ec5c9000 {
			compatible = "renesas,rcar-i2s-ssi";
			reg = <0xec5c9000 0x34>,
			      <0xec5c0000 0xa004>,
			      <0xec140000 0x7004>;
			reg-names = "ssi", "ssiu", "ssip";
			dmas = <&audio_dmac0 0 0x26>,
			       <&audio_dmac0 1 0x27>;
			dma-names = "rx", "tx";
			interrupts = <GIC_SPI 521 IRQ_TYPE_LEVEL IRQ_DEFAULT_PRIORITY>;
			clocks = <&scmi_clk R8A78000_SCMI_CLK_SSI08>,
				 <&scmi_clk R8A78000_SCMI_CLK_SSI0>,
				 <&adg0 ADG_CLKSRC(BRGA)>;
			clock-names = "ssi", "ssi-domain", "audio-clk";
			#address-cells = <1>;
			#size-cells = <0>;
			status = "disabled";
		};

		ssi9: ssi@ec5d9000 {
			compatible = "renesas,rcar-i2s-ssi";
			reg = <0xec5d9000 0x34>,
			      <0xec5d0000 0xa004>,
			      <0xec148000 0x7004>;
			reg-names = "ssi", "ssiu", "ssip";
			dmas = <&audio_dmac0 0 0x24>,
			       <&audio_dmac0 1 0x25>;
			dma-names = "rx", "tx";
			interrupts = <GIC_SPI 522 IRQ_TYPE_LEVEL IRQ_DEFAULT_PRIORITY>;
			clocks = <&scmi_clk R8A78000_SCMI_CLK_SSI09>,
				 <&scmi_clk R8A78000_SCMI_CLK_SSI0>,
				 <&adg0 ADG_CLKSRC(BRGA)>;
			clock-names = "ssi", "ssi-domain", "audio-clk";
			#address-cells = <1>;
			#size-cells = <0>;
			status = "disabled";
		};

		ssi10: ssi@ed549000 {
			compatible = "renesas,rcar-i2s-ssi";
			reg = <0xed549000 0x34>,
			      <0xed540000 0xa004>,
			      <0xed100000 0x7004>;
			reg-names = "ssi", "ssiu", "ssip";
			dmas = <&audio_dmac2 0 0x7c>,
			       <&audio_dmac2 1 0x7d>;
			dma-names = "rx", "tx";
			interrupts = <GIC_SPI 523 IRQ_TYPE_LEVEL IRQ_DEFAULT_PRIORITY>;
			clocks = <&scmi_clk R8A78000_SCMI_CLK_SSI10>,
				 <&scmi_clk R8A78000_SCMI_CLK_SSI1>,
				 <&adg1 ADG_CLKSRC(BRGA)>;
			clock-names = "ssi", "ssi-domain", "audio-clk";
			#address-cells = <1>;
			#size-cells = <0>;
			status = "disabled";
		};

		ssi11: ssi@ed559000 {
			compatible = "renesas,rcar-i2s-ssi";
			reg = <0xed559000 0x34>,
			      <0xed550000 0xa004>,
			      <0xed108000 0x7004>;
			reg-names = "ssi", "ssiu", "ssip";
			dmas = <&audio_dmac2 0 0x6c>,
			       <&audio_dmac2 1 0x6d>;
			dma-names = "rx", "tx";
			interrupts = <GIC_SPI 524 IRQ_TYPE_LEVEL IRQ_DEFAULT_PRIORITY>;
			clocks = <&scmi_clk R8A78000_SCMI_CLK_SSI11>,
				 <&scmi_clk R8A78000_SCMI_CLK_SSI1>,
				 <&adg1 ADG_CLKSRC(BRGA)>;
			clock-names = "ssi", "ssi-domain", "audio-clk";
			#address-cells = <1>;
			#size-cells = <0>;
			status = "disabled";
		};

		ssi12: ssi@ed569000 {
			compatible = "renesas,rcar-i2s-ssi";
			reg = <0xed569000 0x34>,
			      <0xed560000 0xa004>,
			      <0xed110000 0x7004>;
			reg-names = "ssi", "ssiu", "ssip";
			dmas = <&audio_dmac2 0 0x5c>,
			       <&audio_dmac2 1 0x5d>;
			dma-names = "rx", "tx";
			interrupts = <GIC_SPI 525 IRQ_TYPE_LEVEL IRQ_DEFAULT_PRIORITY>;
			clocks = <&scmi_clk R8A78000_SCMI_CLK_SSI12>,
				 <&scmi_clk R8A78000_SCMI_CLK_SSI1>,
				 <&adg1 ADG_CLKSRC(BRGA)>;
			clock-names = "ssi", "ssi-domain", "audio-clk";
			#address-cells = <1>;
			#size-cells = <0>;
			status = "disabled";
		};

		ssi13: ssi@ed579000 {
			compatible = "renesas,rcar-i2s-ssi";
			reg = <0xed579000 0x34>,
			      <0xed570000 0xa004>,
			      <0xed118000 0x7004>;
			reg-names = "ssi", "ssiu", "ssip";
			dmas = <&audio_dmac2 0 0x4c>,
			       <&audio_dmac2 1 0x4d>;
			dma-names = "rx", "tx";
			interrupts = <GIC_SPI 526 IRQ_TYPE_LEVEL IRQ_DEFAULT_PRIORITY>;
			clocks = <&scmi_clk R8A78000_SCMI_CLK_SSI13>,
				 <&scmi_clk R8A78000_SCMI_CLK_SSI1>,
				 <&adg1 ADG_CLKSRC(BRGA)>;
			clock-names = "ssi", "ssi-domain", "audio-clk";
			#address-cells = <1>;
			#size-cells = <0>;
			status = "disabled";
		};

		ssi14: ssi@ed589000 {
			compatible = "renesas,rcar-i2s-ssi";
			reg = <0xed589000 0x34>,
			      <0xed580000 0xa004>,
			      <0xed120000 0x7004>;
			reg-names = "ssi", "ssiu", "ssip";
			dmas = <&audio_dmac2 0 0x3c>,
			       <&audio_dmac2 1 0x3d>;
			dma-names = "rx", "tx";
			interrupts = <GIC_SPI 527 IRQ_TYPE_LEVEL IRQ_DEFAULT_PRIORITY>;
			clocks = <&scmi_clk R8A78000_SCMI_CLK_SSI14>,
				 <&scmi_clk R8A78000_SCMI_CLK_SSI1>,
				 <&adg1 ADG_CLKSRC(BRGA)>;
			clock-names = "ssi", "ssi-domain", "audio-clk";
			#address-cells = <1>;
			#size-cells = <0>;
			status = "disabled";
		};

		ssi15: ssi@ed599000 {
			compatible = "renesas,rcar-i2s-ssi";
			reg = <0xed599000 0x34>,
			      <0xed590000 0xa004>,
			      <0xed128000 0x7004>;
			reg-names = "ssi", "ssiu", "ssip";
			dmas = <&audio_dmac2 0 0x2c>,
			       <&audio_dmac2 1 0x2d>;
			dma-names = "rx", "tx";
			interrupts = <GIC_SPI 528 IRQ_TYPE_LEVEL IRQ_DEFAULT_PRIORITY>;
			clocks = <&scmi_clk R8A78000_SCMI_CLK_SSI15>,
				 <&scmi_clk R8A78000_SCMI_CLK_SSI1>,
				 <&adg1 ADG_CLKSRC(BRGA)>;
			clock-names = "ssi", "ssi-domain", "audio-clk";
			#address-cells = <1>;
			#size-cells = <0>;
			status = "disabled";
		};

		ssi16: ssi@ed5a9000 {
			compatible = "renesas,rcar-i2s-ssi";
			reg = <0xed5a9000 0x34>,
			      <0xed5a0000 0xa004>,
			      <0xed130000 0x7004>;
			reg-names = "ssi", "ssiu", "ssip";
			dmas = <&audio_dmac2 0 0x2a>,
			       <&audio_dmac2 1 0x2b>;
			dma-names = "rx", "tx";
			interrupts = <GIC_SPI 529 IRQ_TYPE_LEVEL IRQ_DEFAULT_PRIORITY>;
			clocks = <&scmi_clk R8A78000_SCMI_CLK_SSI16>,
				 <&scmi_clk R8A78000_SCMI_CLK_SSI1>,
				 <&adg1 ADG_CLKSRC(BRGA)>;
			clock-names = "ssi", "ssi-domain", "audio-clk";
			#address-cells = <1>;
			#size-cells = <0>;
			status = "disabled";
		};

		ssi17: ssi@ed5b9000 {
			compatible = "renesas,rcar-i2s-ssi";
			reg = <0xed5b9000 0x34>,
			      <0xed5b0000 0xa004>,
			      <0xed138000 0x7004>;
			reg-names = "ssi", "ssiu", "ssip";
			dmas = <&audio_dmac2 0 0x28>,
			       <&audio_dmac2 1 0x29>;
			dma-names = "rx", "tx";
			interrupts = <GIC_SPI 530 IRQ_TYPE_LEVEL IRQ_DEFAULT_PRIORITY>;
			clocks = <&scmi_clk R8A78000_SCMI_CLK_SSI17>,
				 <&scmi_clk R8A78000_SCMI_CLK_SSI1>,
				 <&adg1 ADG_CLKSRC(BRGA)>;
			clock-names = "ssi", "ssi-domain", "audio-clk";
			#address-cells = <1>;
			#size-cells = <0>;
			status = "disabled";
		};

		ssi18: ssi@ed5c9000 {
			compatible = "renesas,rcar-i2s-ssi";
			reg = <0xed5c9000 0x34>,
			      <0xed5c0000 0xa004>,
			      <0xed140000 0x7004>;
			reg-names = "ssi", "ssiu", "ssip";
			dmas = <&audio_dmac2 0 0x26>,
			       <&audio_dmac2 1 0x27>;
			dma-names = "rx", "tx";
			interrupts = <GIC_SPI 531 IRQ_TYPE_LEVEL IRQ_DEFAULT_PRIORITY>;
			clocks = <&scmi_clk R8A78000_SCMI_CLK_SSI18>,
				 <&scmi_clk R8A78000_SCMI_CLK_SSI1>,
				 <&adg1 ADG_CLKSRC(BRGA)>;
			clock-names = "ssi", "ssi-domain", "audio-clk";
			#address-cells = <1>;
			#size-cells = <0>;
			status = "disabled";
		};

		ssi19: ssi@ed5d9000 {
			compatible = "renesas,rcar-i2s-ssi";
			reg = <0xed5d9000 0x34>,
			      <0xed5d0000 0xa004>,
			      <0xed148000 0x7004>;
			reg-names = "ssi", "ssiu", "ssip";
			dmas = <&audio_dmac2 0 0x24>,
			       <&audio_dmac2 1 0x25>;
			dma-names = "rx", "tx";
			interrupts = <GIC_SPI 532 IRQ_TYPE_LEVEL IRQ_DEFAULT_PRIORITY>;
			clocks = <&scmi_clk R8A78000_SCMI_CLK_SSI19>,
				 <&scmi_clk R8A78000_SCMI_CLK_SSI1>,
				 <&adg1 ADG_CLKSRC(BRGA)>;
			clock-names = "ssi", "ssi-domain", "audio-clk";
			#address-cells = <1>;
			#size-cells = <0>;
			status = "disabled";
		};

		mdio0: mdio@c9b9e000 {
			compatible = "renesas,rcar-rsw3-mdio";
			reg = <0xc9b9e000 0x1000>,
			      <0xc9b80000 0x40000>;
			reg-names = "rmac", "base_secure";
			clocks = <&scmi_clk R8A78000_SCMI_CLK_CORE_RSW3_AES>,
				 <&rsw3_aes_clk>;
			clock-names = "gate", "mdc-source";
			channel = <0>;
			#address-cells = <1>;
			#size-cells = <0>;
			status = "disabled";
		};

		mdio1: mdio@c9ba0000 {
			compatible = "renesas,rcar-rsw3-mdio";
			reg = <0xc9ba0000 0x1000>,
			      <0xc9b80000 0x40000>;
			reg-names = "rmac", "base_secure";
			clocks = <&scmi_clk R8A78000_SCMI_CLK_CORE_RSW3_AES>,
				 <&rsw3_aes_clk>;
			clock-names = "gate", "mdc-source";
			channel = <1>;
			#address-cells = <1>;
			#size-cells = <0>;
			status = "disabled";
		};

		mdio2: mdio@c9ba2000 {
			compatible = "renesas,rcar-rsw3-mdio";
			reg = <0xc9ba2000 0x1000>,
			      <0xc9b80000 0x40000>;
			reg-names = "rmac", "base_secure";
			clocks = <&scmi_clk R8A78000_SCMI_CLK_CORE_RSW3_AES>,
				 <&rsw3_aes_clk>;
			clock-names = "gate", "mdc-source";
			channel = <2>;
			#address-cells = <1>;
			#size-cells = <0>;
			status = "disabled";
		};

		mdio3: mdio@c9ba4000 {
			compatible = "renesas,rcar-rsw3-mdio";
			reg = <0xc9ba4000 0x1000>,
			      <0xc9b80000 0x40000>;
			reg-names = "rmac", "base_secure";
			clocks = <&scmi_clk R8A78000_SCMI_CLK_CORE_RSW3_AES>,
				 <&rsw3_aes_clk>;
			clock-names = "gate", "mdc-source";
			channel = <3>;
			#address-cells = <1>;
			#size-cells = <0>;
			status = "disabled";
		};

		mdio4: mdio@c9ba6000 {
			compatible = "renesas,rcar-rsw3-mdio";
			reg = <0xc9ba6000 0x1000>,
			      <0xc9b80000 0x40000>;
			reg-names = "rmac", "base_secure";
			clocks = <&scmi_clk R8A78000_SCMI_CLK_CORE_RSW3_AES>,
				 <&rsw3_aes_clk>;
			clock-names = "gate", "mdc-source";
			channel = <4>;
			#address-cells = <1>;
			#size-cells = <0>;
			status = "disabled";
		};

		mp_phy: mp_phy@c9a00000 {
			clocks = <&scmi_clk R8A78000_SCMI_CLK_MPPHY01>,
				 <&scmi_clk R8A78000_SCMI_CLK_MPPHY11>,
				 <&scmi_clk R8A78000_SCMI_CLK_MPPHY21>,
				 <&scmi_clk R8A78000_SCMI_CLK_MPPHY31>,
				 <&scmi_clk R8A78000_SCMI_CLK_MPPHY02>;
		};

		mfis_common: mailbox@18800000 {
			interrupts =
				     /* ch0 S->R */
				     <GIC_SPI 54 IRQ_TYPE_LEVEL IRQ_DEFAULT_PRIORITY>,
				     /* ch0 R->S */
				     <GIC_SPI 55 IRQ_TYPE_LEVEL IRQ_DEFAULT_PRIORITY>,
				     /* ch1 S->R */
				     <GIC_SPI 56 IRQ_TYPE_LEVEL IRQ_DEFAULT_PRIORITY>,
				     /* ch1 R->S */
				     <GIC_SPI 57 IRQ_TYPE_LEVEL IRQ_DEFAULT_PRIORITY>,
				     /* ch2 S->R */
				     <GIC_SPI 58 IRQ_TYPE_LEVEL IRQ_DEFAULT_PRIORITY>,
				     /* ch2 R->S */
				     <GIC_SPI 59 IRQ_TYPE_LEVEL IRQ_DEFAULT_PRIORITY>,
				     /* ch3 S->R */
				     <GIC_SPI 60 IRQ_TYPE_LEVEL IRQ_DEFAULT_PRIORITY>,
				     /* ch3 R->S */
				     <GIC_SPI 61 IRQ_TYPE_LEVEL IRQ_DEFAULT_PRIORITY>,
				     /* ch4 S->R */
				     <GIC_SPI 62 IRQ_TYPE_LEVEL IRQ_DEFAULT_PRIORITY>,
				     /* ch4 R->S */
				     <GIC_SPI 63 IRQ_TYPE_LEVEL IRQ_DEFAULT_PRIORITY>,
				     /* ch5 S->R */
				     <GIC_SPI 64 IRQ_TYPE_LEVEL IRQ_DEFAULT_PRIORITY>,
				     /* ch5 R->S */
				     <GIC_SPI 65 IRQ_TYPE_LEVEL IRQ_DEFAULT_PRIORITY>,
				     /* ch6 S->R */
				     <GIC_SPI 66 IRQ_TYPE_LEVEL IRQ_DEFAULT_PRIORITY>,
				     /* ch6 R->S */
				     <GIC_SPI 67 IRQ_TYPE_LEVEL IRQ_DEFAULT_PRIORITY>,
				     /* ch7 S->R */
				     <GIC_SPI 68 IRQ_TYPE_LEVEL IRQ_DEFAULT_PRIORITY>,
				     /* ch7 R->S */
				     <GIC_SPI 69 IRQ_TYPE_LEVEL IRQ_DEFAULT_PRIORITY>,
				     /* ch8 S->R */
				     <GIC_SPI 70 IRQ_TYPE_LEVEL IRQ_DEFAULT_PRIORITY>,
				     /* ch8 R->S */
				     <GIC_SPI 71 IRQ_TYPE_LEVEL IRQ_DEFAULT_PRIORITY>,
				     /* ch9 S->R */
				     <GIC_SPI 72 IRQ_TYPE_LEVEL IRQ_DEFAULT_PRIORITY>,
				     /* ch9 R->S */
				     <GIC_SPI 73 IRQ_TYPE_LEVEL IRQ_DEFAULT_PRIORITY>,
				     /* ch10 S->R */
				     <GIC_SPI 74 IRQ_TYPE_LEVEL IRQ_DEFAULT_PRIORITY>,
				     /* ch10 R->S */
				     <GIC_SPI 75 IRQ_TYPE_LEVEL IRQ_DEFAULT_PRIORITY>,
				     /* ch11 S->R */
				     <GIC_SPI 76 IRQ_TYPE_LEVEL IRQ_DEFAULT_PRIORITY>,
				     /* ch11 R->S */
				     <GIC_SPI 77 IRQ_TYPE_LEVEL IRQ_DEFAULT_PRIORITY>,
				     /* ch12 S->R */
				     <GIC_SPI 78 IRQ_TYPE_LEVEL IRQ_DEFAULT_PRIORITY>,
				     /* ch12 R->S */
				     <GIC_SPI 79 IRQ_TYPE_LEVEL IRQ_DEFAULT_PRIORITY>,
				     /* ch13 S->R */
				     <GIC_SPI 80 IRQ_TYPE_LEVEL IRQ_DEFAULT_PRIORITY>,
				     /* ch13 R->S */
				     <GIC_SPI 81 IRQ_TYPE_LEVEL IRQ_DEFAULT_PRIORITY>,
				     /* ch14 S->R */
				     <GIC_SPI 82 IRQ_TYPE_LEVEL IRQ_DEFAULT_PRIORITY>,
				     /* ch14 R->S */
				     <GIC_SPI 83 IRQ_TYPE_LEVEL IRQ_DEFAULT_PRIORITY>,
				     /* ch15 S->R */
				     <GIC_SPI 84 IRQ_TYPE_LEVEL IRQ_DEFAULT_PRIORITY>,
				     /* ch15 R->S */
				     <GIC_SPI 85 IRQ_TYPE_LEVEL IRQ_DEFAULT_PRIORITY>,
				     /* ch16 S->R */
				     <GIC_SPI 86 IRQ_TYPE_LEVEL IRQ_DEFAULT_PRIORITY>,
				     /* ch16 R->S */
				     <GIC_SPI 87 IRQ_TYPE_LEVEL IRQ_DEFAULT_PRIORITY>,
				     /* ch17 S->R */
				     <GIC_SPI 88 IRQ_TYPE_LEVEL IRQ_DEFAULT_PRIORITY>,
				     /* ch17 R->S */
				     <GIC_SPI 89 IRQ_TYPE_LEVEL IRQ_DEFAULT_PRIORITY>,
				     /* ch18 S->R */
				     <GIC_SPI 90 IRQ_TYPE_LEVEL IRQ_DEFAULT_PRIORITY>,
				     /* ch18 R->S */
				     <GIC_SPI 91 IRQ_TYPE_LEVEL IRQ_DEFAULT_PRIORITY>,
				     /* ch19 S->R */
				     <GIC_SPI 92 IRQ_TYPE_LEVEL IRQ_DEFAULT_PRIORITY>,
				     /* ch19 R->S */
				     <GIC_SPI 93 IRQ_TYPE_LEVEL IRQ_DEFAULT_PRIORITY>,
				     /* ch20 S->R */
				     <GIC_SPI 94 IRQ_TYPE_LEVEL IRQ_DEFAULT_PRIORITY>,
				     /* ch20 R->S */
				     <GIC_SPI 95 IRQ_TYPE_LEVEL IRQ_DEFAULT_PRIORITY>,
				     /* ch21 S->R */
				     <GIC_SPI 96 IRQ_TYPE_LEVEL IRQ_DEFAULT_PRIORITY>,
				     /* ch21 R->S */
				     <GIC_SPI 97 IRQ_TYPE_LEVEL IRQ_DEFAULT_PRIORITY>,
				     /* ch22 S->R */
				     <GIC_SPI 98 IRQ_TYPE_LEVEL IRQ_DEFAULT_PRIORITY>,
				     /* ch22 R->S */
				     <GIC_SPI 99 IRQ_TYPE_LEVEL IRQ_DEFAULT_PRIORITY>,
				     /* ch23 S->R */
				     <GIC_SPI 100 IRQ_TYPE_LEVEL IRQ_DEFAULT_PRIORITY>,
				     /* ch23 R->S */
				     <GIC_SPI 101 IRQ_TYPE_LEVEL IRQ_DEFAULT_PRIORITY>,
				     /* ch24 S->R */
				     <GIC_SPI 102 IRQ_TYPE_LEVEL IRQ_DEFAULT_PRIORITY>,
				     /* ch24 R->S */
				     <GIC_SPI 103 IRQ_TYPE_LEVEL IRQ_DEFAULT_PRIORITY>,
				     /* ch25 S->R */
				     <GIC_SPI 104 IRQ_TYPE_LEVEL IRQ_DEFAULT_PRIORITY>,
				     /* ch25 R->S */
				     <GIC_SPI 105 IRQ_TYPE_LEVEL IRQ_DEFAULT_PRIORITY>,
				     /* ch26 S->R */
				     <GIC_SPI 106 IRQ_TYPE_LEVEL IRQ_DEFAULT_PRIORITY>,
				     /* ch26 R->S */
				     <GIC_SPI 107 IRQ_TYPE_LEVEL IRQ_DEFAULT_PRIORITY>,
				     /* ch27 S->R */
				     <GIC_SPI 108 IRQ_TYPE_LEVEL IRQ_DEFAULT_PRIORITY>,
				     /* ch27 R->S */
				     <GIC_SPI 109 IRQ_TYPE_LEVEL IRQ_DEFAULT_PRIORITY>,
				     /* ch28 S->R */
				     <GIC_SPI 110 IRQ_TYPE_LEVEL IRQ_DEFAULT_PRIORITY>,
				     /* ch28 R->S */
				     <GIC_SPI 111 IRQ_TYPE_LEVEL IRQ_DEFAULT_PRIORITY>,
				     /* ch29 S->R */
				     <GIC_SPI 112 IRQ_TYPE_LEVEL IRQ_DEFAULT_PRIORITY>,
				     /* ch29 R->S */
				     <GIC_SPI 113 IRQ_TYPE_LEVEL IRQ_DEFAULT_PRIORITY>,
				     /* ch30 S->R */
				     <GIC_SPI 114 IRQ_TYPE_LEVEL IRQ_DEFAULT_PRIORITY>,
				     /* ch30 R->S */
				     <GIC_SPI 115 IRQ_TYPE_LEVEL IRQ_DEFAULT_PRIORITY>,
				     /* ch31 S->R */
				     <GIC_SPI 116 IRQ_TYPE_LEVEL IRQ_DEFAULT_PRIORITY>,
				     /* ch31 R->S */
				     <GIC_SPI 117 IRQ_TYPE_LEVEL IRQ_DEFAULT_PRIORITY>,
				     /* ch32 S->R */
				     <GIC_SPI 118 IRQ_TYPE_LEVEL IRQ_DEFAULT_PRIORITY>,
				     /* ch32 R->S */
				     <GIC_SPI 119 IRQ_TYPE_LEVEL IRQ_DEFAULT_PRIORITY>,
				     /* ch33 S->R */
				     <GIC_SPI 120 IRQ_TYPE_LEVEL IRQ_DEFAULT_PRIORITY>,
				     /* ch33 R->S */
				     <GIC_SPI 121 IRQ_TYPE_LEVEL IRQ_DEFAULT_PRIORITY>,
				     /* ch34 S->R */
				     <GIC_SPI 122 IRQ_TYPE_LEVEL IRQ_DEFAULT_PRIORITY>,
				     /* ch34 R->S */
				     <GIC_SPI 123 IRQ_TYPE_LEVEL IRQ_DEFAULT_PRIORITY>,
				     /* ch35 S->R */
				     <GIC_SPI 124 IRQ_TYPE_LEVEL IRQ_DEFAULT_PRIORITY>,
				     /* ch35 R->S */
				     <GIC_SPI 125 IRQ_TYPE_LEVEL IRQ_DEFAULT_PRIORITY>,
				     /* ch36 S->R */
				     <GIC_SPI 126 IRQ_TYPE_LEVEL IRQ_DEFAULT_PRIORITY>,
				     /* ch36 R->S */
				     <GIC_SPI 127 IRQ_TYPE_LEVEL IRQ_DEFAULT_PRIORITY>,
				     /* ch37 S->R */
				     <GIC_SPI 128 IRQ_TYPE_LEVEL IRQ_DEFAULT_PRIORITY>,
				     /* ch37 R->S */
				     <GIC_SPI 129 IRQ_TYPE_LEVEL IRQ_DEFAULT_PRIORITY>,
				     /* ch38 S->R */
				     <GIC_SPI 130 IRQ_TYPE_LEVEL IRQ_DEFAULT_PRIORITY>,
				     /* ch38 R->S */
				     <GIC_SPI 131 IRQ_TYPE_LEVEL IRQ_DEFAULT_PRIORITY>,
				     /* ch39 S->R */
				     <GIC_SPI 132 IRQ_TYPE_LEVEL IRQ_DEFAULT_PRIORITY>,
				     /* ch39 R->S */
				     <GIC_SPI 133 IRQ_TYPE_LEVEL IRQ_DEFAULT_PRIORITY>,
				     /* ch40 S->R */
				     <GIC_SPI 134 IRQ_TYPE_LEVEL IRQ_DEFAULT_PRIORITY>,
				     /* ch40 R->S */
				     <GIC_SPI 135 IRQ_TYPE_LEVEL IRQ_DEFAULT_PRIORITY>,
				     /* ch41 S->R */
				     <GIC_SPI 136 IRQ_TYPE_LEVEL IRQ_DEFAULT_PRIORITY>,
				     /* ch41 R->S */
				     <GIC_SPI 137 IRQ_TYPE_LEVEL IRQ_DEFAULT_PRIORITY>,
				     /* ch42 S->R */
				     <GIC_SPI 138 IRQ_TYPE_LEVEL IRQ_DEFAULT_PRIORITY>,
				     /* ch42 R->S */
				     <GIC_SPI 139 IRQ_TYPE_LEVEL IRQ_DEFAULT_PRIORITY>,
				     /* ch43 S->R */
				     <GIC_SPI 140 IRQ_TYPE_LEVEL IRQ_DEFAULT_PRIORITY>,
				     /* ch43 R->S */
				     <GIC_SPI 141 IRQ_TYPE_LEVEL IRQ_DEFAULT_PRIORITY>,
				     /* ch44 S->R */
				     <GIC_SPI 142 IRQ_TYPE_LEVEL IRQ_DEFAULT_PRIORITY>,
				     /* ch44 R->S */
				     <GIC_SPI 143 IRQ_TYPE_LEVEL IRQ_DEFAULT_PRIORITY>,
				     /* ch45 S->R */
				     <GIC_SPI 144 IRQ_TYPE_LEVEL IRQ_DEFAULT_PRIORITY>,
				     /* ch45 R->S */
				     <GIC_SPI 145 IRQ_TYPE_LEVEL IRQ_DEFAULT_PRIORITY>,
				     /* ch46 S->R */
				     <GIC_SPI 146 IRQ_TYPE_LEVEL IRQ_DEFAULT_PRIORITY>,
				     /* ch46 R->S */
				     <GIC_SPI 147 IRQ_TYPE_LEVEL IRQ_DEFAULT_PRIORITY>,
				     /* ch47 S->R */
				     <GIC_SPI 148 IRQ_TYPE_LEVEL IRQ_DEFAULT_PRIORITY>,
				     /* ch47 R->S */
				     <GIC_SPI 149 IRQ_TYPE_LEVEL IRQ_DEFAULT_PRIORITY>,
				     /* ch48 S->R */
				     <GIC_SPI 150 IRQ_TYPE_LEVEL IRQ_DEFAULT_PRIORITY>,
				     /* ch48 R->S */
				     <GIC_SPI 151 IRQ_TYPE_LEVEL IRQ_DEFAULT_PRIORITY>,
				     /* ch49 S->R */
				     <GIC_SPI 152 IRQ_TYPE_LEVEL IRQ_DEFAULT_PRIORITY>,
				     /* ch49 R->S */
				     <GIC_SPI 153 IRQ_TYPE_LEVEL IRQ_DEFAULT_PRIORITY>,
				     /* ch50 S->R */
				     <GIC_SPI 154 IRQ_TYPE_LEVEL IRQ_DEFAULT_PRIORITY>,
				     /* ch50 R->S */
				     <GIC_SPI 155 IRQ_TYPE_LEVEL IRQ_DEFAULT_PRIORITY>,
				     /* ch51 S->R */
				     <GIC_SPI 156 IRQ_TYPE_LEVEL IRQ_DEFAULT_PRIORITY>,
				     /* ch51 R->S */
				     <GIC_SPI 157 IRQ_TYPE_LEVEL IRQ_DEFAULT_PRIORITY>,
				     /* ch52 S->R */
				     <GIC_SPI 158 IRQ_TYPE_LEVEL IRQ_DEFAULT_PRIORITY>,
				     /* ch52 R->S */
				     <GIC_SPI 159 IRQ_TYPE_LEVEL IRQ_DEFAULT_PRIORITY>,
				     /* ch53 S->R */
				     <GIC_SPI 160 IRQ_TYPE_LEVEL IRQ_DEFAULT_PRIORITY>,
				     /* ch53 R->S */
				     <GIC_SPI 161 IRQ_TYPE_LEVEL IRQ_DEFAULT_PRIORITY>,
				     /* ch54 S->R */
				     <GIC_SPI 162 IRQ_TYPE_LEVEL IRQ_DEFAULT_PRIORITY>,
				     /* ch54 R->S */
				     <GIC_SPI 163 IRQ_TYPE_LEVEL IRQ_DEFAULT_PRIORITY>,
				     /* ch55 S->R */
				     <GIC_SPI 164 IRQ_TYPE_LEVEL IRQ_DEFAULT_PRIORITY>,
				     /* ch55 R->S */
				     <GIC_SPI 165 IRQ_TYPE_LEVEL IRQ_DEFAULT_PRIORITY>,
				     /* ch56 S->R */
				     <GIC_SPI 166 IRQ_TYPE_LEVEL IRQ_DEFAULT_PRIORITY>,
				     /* ch56 R->S */
				     <GIC_SPI 167 IRQ_TYPE_LEVEL IRQ_DEFAULT_PRIORITY>,
				     /* ch57 S->R */
				     <GIC_SPI 168 IRQ_TYPE_LEVEL IRQ_DEFAULT_PRIORITY>,
				     /* ch57 R->S */
				     <GIC_SPI 169 IRQ_TYPE_LEVEL IRQ_DEFAULT_PRIORITY>,
				     /* ch58 S->R */
				     <GIC_SPI 170 IRQ_TYPE_LEVEL IRQ_DEFAULT_PRIORITY>,
				     /* ch58 R->S */
				     <GIC_SPI 171 IRQ_TYPE_LEVEL IRQ_DEFAULT_PRIORITY>,
				     /* ch59 S->R */
				     <GIC_SPI 172 IRQ_TYPE_LEVEL IRQ_DEFAULT_PRIORITY>,
				     /* ch59 R->S */
				     <GIC_SPI 173 IRQ_TYPE_LEVEL IRQ_DEFAULT_PRIORITY>,
				     /* ch60 S->R */
				     <GIC_SPI 174 IRQ_TYPE_LEVEL IRQ_DEFAULT_PRIORITY>,
				     /* ch60 R->S */
				     <GIC_SPI 175 IRQ_TYPE_LEVEL IRQ_DEFAULT_PRIORITY>,
				     /* ch61 S->R */
				     <GIC_SPI 176 IRQ_TYPE_LEVEL IRQ_DEFAULT_PRIORITY>,
				     /* ch61 R->S */
				     <GIC_SPI 177 IRQ_TYPE_LEVEL IRQ_DEFAULT_PRIORITY>,
				     /* ch62 S->R */
				     <GIC_SPI 178 IRQ_TYPE_LEVEL IRQ_DEFAULT_PRIORITY>,
				     /* ch62 R->S */
				     <GIC_SPI 179 IRQ_TYPE_LEVEL IRQ_DEFAULT_PRIORITY>,
				     /* ch63 S->R */
				     <GIC_SPI 180 IRQ_TYPE_LEVEL IRQ_DEFAULT_PRIORITY>,
				     /* ch63 R->S */
				     <GIC_SPI 181 IRQ_TYPE_LEVEL IRQ_DEFAULT_PRIORITY>;
		};

		mfis_scp: mailbox@18840000 {
			interrupts =
				     /* RT_SCP_ch0 */
				     <GIC_SPI 182 IRQ_TYPE_LEVEL IRQ_DEFAULT_PRIORITY>,
				     /* RT_SCP_ch1 */
				     <GIC_SPI 183 IRQ_TYPE_LEVEL IRQ_DEFAULT_PRIORITY>,
				     /* RT_SCP_ch2 */
				     <GIC_SPI 184 IRQ_TYPE_LEVEL IRQ_DEFAULT_PRIORITY>,
				     /* RT_SCP_ch3 */
				     <GIC_SPI 185 IRQ_TYPE_LEVEL IRQ_DEFAULT_PRIORITY>,
				     /* RT_SCP_ch4 */
				     <GIC_SPI 186 IRQ_TYPE_LEVEL IRQ_DEFAULT_PRIORITY>,
				     /* RT_SCP_ch5 */
				     <GIC_SPI 187 IRQ_TYPE_LEVEL IRQ_DEFAULT_PRIORITY>,
				     /* RT_SCP_ch6 */
				     <GIC_SPI 188 IRQ_TYPE_LEVEL IRQ_DEFAULT_PRIORITY>,
				     /* RT_SCP_ch7 */
				     <GIC_SPI 189 IRQ_TYPE_LEVEL IRQ_DEFAULT_PRIORITY>,
				     /* RT_SCP_ch8 */
				     <GIC_SPI 190 IRQ_TYPE_LEVEL IRQ_DEFAULT_PRIORITY>,
				     /* RT_SCP_ch9 */
				     <GIC_SPI 191 IRQ_TYPE_LEVEL IRQ_DEFAULT_PRIORITY>,
				     /* RT_SCP_ch10 */
				     <GIC_SPI 192 IRQ_TYPE_LEVEL IRQ_DEFAULT_PRIORITY>,
				     /* RT_SCP_ch11 */
				     <GIC_SPI 193 IRQ_TYPE_LEVEL IRQ_DEFAULT_PRIORITY>;
		};
	};

	clocks: clocks {
		audio_clk_a: audio-clk-a {
			compatible = "fixed-clock";
			#clock-cells = <0>;
			clock-frequency = <0>;
		};

		audio_clk_b: audio-clk-b {
			compatible = "fixed-clock";
			#clock-cells = <0>;
			clock-frequency = <0>;
		};

		audio_clk_c: audio-clk-c {
			compatible = "fixed-clock";
			#clock-cells = <0>;
			clock-frequency = <0>;
		};

		rclk: rclk {
			compatible = "fixed-clock";
			#clock-cells = <0>;
			clock-frequency = <32768>;
		};

		rsw3_aes_clk: rsw3-aes-clk {
			compatible = "fixed-clock";
			#clock-cells = <0>;
			clock-frequency = <0>;
		};
	};
};
